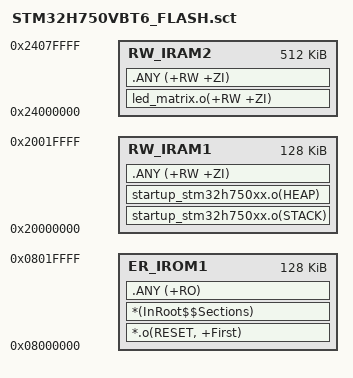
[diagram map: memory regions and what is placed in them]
; *************************************************************
; *** Scatter-Loading Description File for STM32H750VBT6     ***
; *** RAM: 640KB (128KB DTCM + 512KB AXI SRAM)               ***
; *************************************************************

LR_IROM1 0x08000000 0x00020000  {    ; Load region size: 128KB Flash
  ER_IROM1 0x08000000 0x00020000  {  ; Execution region
   *.o(RESET, +First)
   *(InRoot$$Sections)
   .ANY (+RO)
  }
  
  RW_IRAM1 0x20000000 0x00020000  {  ; DTCM: 128KB - 栈和堆
   startup_stm32h750xx.o(STACK)
   startup_stm32h750xx.o(HEAP)
   .ANY (+RW +ZI)
  }
  
  RW_IRAM2 0x24000000 0x00080000  {  ; AXI SRAM: 512KB - 大型数组
   led_matrix.o(+RW +ZI)
   .ANY (+RW +ZI)
  }
}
